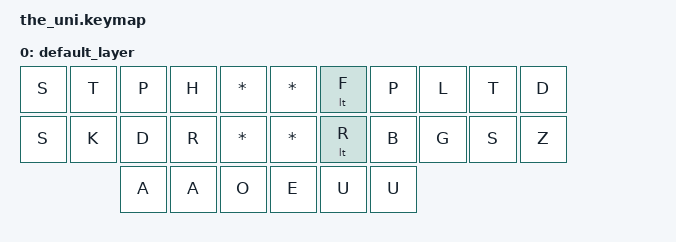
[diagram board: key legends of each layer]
/*
* Copyright (c) 2021 The ZMK Contributors
*
* SPDX-License-Identifier: MIT
*/

#include <behaviors.dtsi>
#include <dt-bindings/zmk/keys.h>

/ {
    keymap {
        compatible = "zmk,keymap";

        default_layer {
// ---------------------------------------------------
// | S | T | P | H | * |     | * | F | P | L | T | D |
// | S | K | W | R | * |     | * | R | B | G | S | Z |
//         | A | A | O |     | E | U | U |

            bindings = <
                &kp S    &kp T    &kp P    &kp H    &kp STAR      &kp STAR &lt F    &kp P    &kp L    &kp T    &kp D
                &kp S    &kp K    &kp D    &kp R    &kp STAR      &kp STAR &lt R    &kp B    &kp G    &kp S    &kp Z
                                  &kp A    &kp A    &kp O         &kp E    &kp U    &kp U
            >;
        };
    };
};
